# A64 register map
Vendor: Allwinner; Series: A64; File version: 0.1
CPU: CA53 0, little endian, MPU, no FPU, 0 interrupt priority bits
Registers are 32-bit, read-write, reset 0x0 unless marked. A register's access mark holds for its fields unless they carry their own. Offsets are from the block's base; [hi:lo] are bit positions; lines under a group give offsets from that group; {n}, {i} and the like mark numbered series; <NAME> marks a mode.

## SMC
Base 0x01C1E000
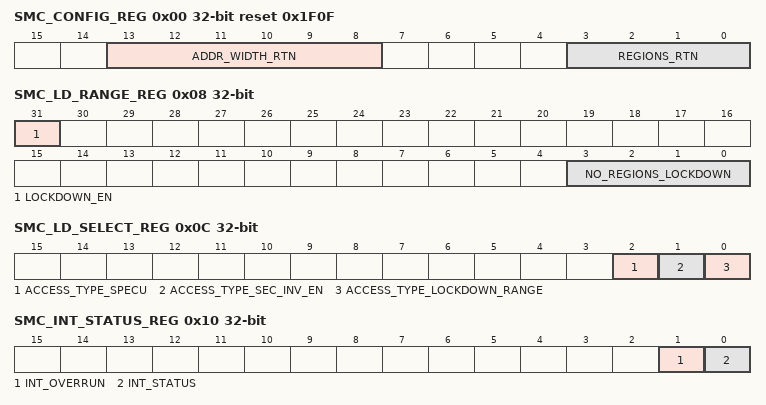
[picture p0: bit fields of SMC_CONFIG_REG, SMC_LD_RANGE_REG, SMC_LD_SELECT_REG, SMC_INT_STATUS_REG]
0x00 SMC_CONFIG_REG reset 0x1F0F — SMC Configuration Register
  [13:8] ADDR_WIDTH_RTN ro — Address width. Return the width of the AXI address bus. 6`b 000000-6`b011110 reserved. 6`b 011111 = 32-bit ... 6`b 111111 = 64-bit
  [3:0] REGIONS_RTN ro — Returns the number of the regions that the SMC provides. 4`b0000 = reserved 4`b0001 = 2 regions ... 4`b1111 = 16 regions.
0x04 SMC_ACTION_REG reset 0x1 — SMC Action Register
  [1:0] SMC_INT_RESP — Control how the SMC uses the bresps[1:0], rresps[1:0], and smc_int signals when a region permission failure occurs: 2`b00 = sets smc_int LOW and issues an OKEY response 2`b01 = sets smc_int LOW and issues a DECERR response 2`b10 = sets smc_int HIGH and issues an OKEY response 2`b11 = sets smc_int HIGH and issues a DECERR response
0x08 SMC_LD_RANGE_REG — SMC Lock Down Range Register
  [31] LOCKDOWN_EN — When set to 1, it enables the lockdown_regions field to control the regions that are to be locked.
  [3:0] NO_REGIONS_LOCKDOWN — Control the number of regions to lockdown when the enable bit is set to 1. 4`b0000 = region no_of_regions-1 is locked 4`b0001 = region no_of_regions-1 to region no_of_regions-2 are locked ... 4`b1111 = region no_of_regions-1 to region no_of_regions-16 are locked
0x0C SMC_LD_SELECT_REG — SMC Lock Down Select Register
  [2] ACCESS_TYPE_SPECU — Modify the access type of the speculation_control register: 0: no effect. The speculation register remains RW. 1: speculation_control register is RO
    0=no effect. The speculation register remains RW.; 1=speculation_control register is RO
  [1] ACCESS_TYPE_SEC_INV_EN — Modify the access type of the security_inversion_en register. 0: no effect. Security_inversion_en register remains RW. 1: security_inversion_en register is RO
    0=no effect. Security_inversion_en register remains RW.; 1=security_inversion_en register is RO
  [0] ACCESS_TYPE_LOCKDOWN_RANGE — Modify the access type of the lockdown_range register. 0: no effect. Lockdown_range register remains RW 1: lockdown_range register is RO.
    0=no effect. Lockdown_range register remains RW; 1=lockdown_range register is RO
0x10 SMC_INT_STATUS_REG — SMC Interrupt Status Register
  [1] INT_OVERRUN ro — When set to 1, it indicates the occurrence of two or more region permission failure since the interrupt was last cleared.
  [0] INT_STATUS ro — Return the status of the interrupt. 0: interrupt is inactive. 1: interrupt is active.
    0=inactive (interrupt is inactive.); 1=active (interrupt is active.)
0x14 SMC_INT_CLEAR_REG — SMC Interrupt Clear Register
  [31:0] SMC_CLR_REG — Write any value to the int_clear register sets the : Status bit to 0 in the int_status register Overrun bit to 0 in the int_status register. Note: It will be auto cleared after the write operation.
0x18 SMC_MST_BYP_REG reset 0xFFFFFFFF — SMC Master Bypass Register
  [31:0] SMC_MASTER_BYPASS_EN — SMC Master n Bypass Enable. (n = 0~31, see the . MASTER and MASTER ID for detail.) Note: Bit[31:0] stand for Master ID [31:0] If the master n bypass enable is set to 0, the master n access must be through the SMC. 0: Bypass Disable 1: Bypass Enable.
0x1C SMC_MST_SEC_REG — SMC Master Secure Register
  [31:0] SMC_MASTER_SEC — SMC Master n Secure Configuration.(n = 0~31 see the for detail) 0: secure 1: non-secure.
0x20 SMC_FAIL_ADDR_REG — SMC Fail Address Register
  [31:0] FIRST_ACCESS_FAIL ro — Return the address bits [31:0] of the first access to fail a region permission check after the interrupt was cleared. For external 16-bit DDR2, the address [2:0] is fixed to zero. For external 32-bit DDR2 and 16-bit DDR3, the address [3:0] is fixed to zero. For external 32-bit DDR3, the address [4:0] is fixed to zero.
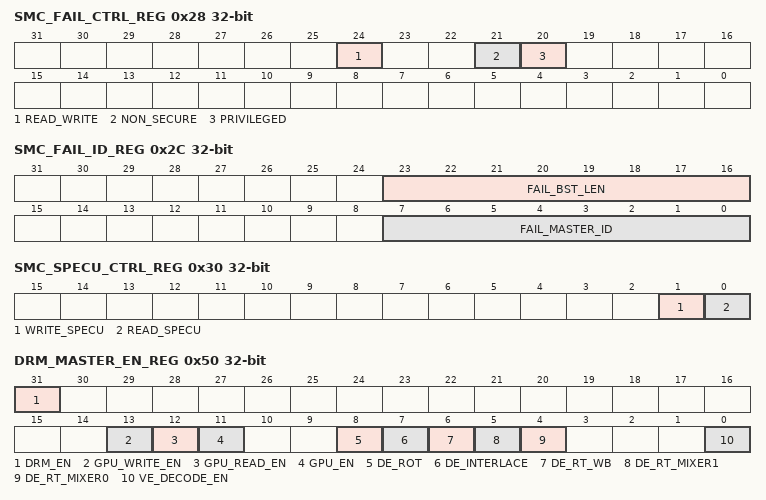
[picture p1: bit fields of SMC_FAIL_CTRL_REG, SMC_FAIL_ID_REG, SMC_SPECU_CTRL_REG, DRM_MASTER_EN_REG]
0x28 SMC_FAIL_CTRL_REG — SMC Fail Control Register
  [24] READ_WRITE ro — This bit indicates whether the first access to fail a region permission check was a write or read as: 0 = read access 1 = write access.
  [21] NON_SECURE ro — After clearing the interrupt status, this bit indicates whether the first access to fail a region permission check was non-secure. Read as: 0 = secure access 1 = non-secure access
  [20] PRIVILEGED ro — After clearing the interrupt status, this bit indicates whether the first access to fail a region permission check was privileged. Read as: 0 = unprivileged access. 1 = privileged access
0x2C SMC_FAIL_ID_REG — SMC Fail ID Register
  [23:16] FAIL_BST_LEN ro — Fail burst length. 0 = 1 word length ... 0xf =16 words length
  [7:0] FAIL_MASTER_ID ro — Fail Master ID. The value stands for master id, see the MASTER and MASTER ID for detail.
0x30 SMC_SPECU_CTRL_REG — SMC Speculation Control Register
  [1] WRITE_SPECU — Write_speculation. Control the write access speculation: 0 = write access speculation is enabled 1 = write access speculation is disabled.
  [0] READ_SPECU — Read_speculation. Control the read access speculation: 0 = read access speculation is enabled 1 = read access speculation is disabled.
0x34 SMC_SEC_INV_EN_REG — SMC Security Inversion Enable Register
  [0] SEC_INV_EN — Security_inversion_en. Controls whether the SMC permits security inversion to occur. 0 = security inversion is not permitted. 1 = security inversion is permitted. This enables a region to be accessible to masters in Non-secure state but not accessible to masters in Secure state. See and .
0x48 SMC_MST_ATTRI_REG — SMC Master Attribute Register
  [31:0] MST_ATTRI — 0: The secure attribute of master is up to master security extensions; 1: The secure attribute of master is up to .
0x50 DRM_MASTER_EN_REG — DRM Master Enable Register
  [31] DRM_EN — DRM enable.
  [13] GPU_WRITE_EN — GPU write enable.
  [12] GPU_READ_EN — GPU read enable.
  [11] GPU_EN — GPU enable When setted the bit to 1,bit12 and bit13 will be invalid.
  [8] DE_ROT — DE_ROT enable
  [7] DE_INTERLACE — DE_INTERLACE enable.
  [6] DE_RT_WB — DE_RT-WB enable.
  [5] DE_RT_MIXER1 — DE_RT-MIXER1 enable.
  [4] DE_RT_MIXER0 — DE_RT-MIXER0 enable.
  [0] VE_DECODE_EN — VE decode enable
0x58 DRM_ILLACCE_REG0
  [31:0] DRM_ILLACCE_REG ro — When a master, which is non-secure, accesses the DRM space, then the relevant bit will be set up. See for detail.
0x60 DRM_STATADDR_REG — DRM Start Address Register
  [31:15] DRM_STATADDR_REG
0x68 DRM_ENDADDR_REG — DRM End Address Register
  [31:15] DRM_ENDADDR_REG
{0x100+0x10*i} _N[{i}] (i=0..15) group
  0x00 SMC_REGION_SETUP_LO_REG — Region Setup Low Register N (N=0,1,2,3,4,5,6,7,8,9,10,11,12,13,14,15)
    [31:15] BASE_ADDRESS_LOW — Controls the base address [31:15] of region<n>. The SMC only permits a region to start at address 0x0, or at a multiple of its region size. For example, if the size of a region is 512MB, and it is not at address 0x0, the only valid settings for this field are: 17`b00100000000000000 17`b01000000000000000 17`b01100000000000000 17`b10000000000000000 17`b10100000000000000 17`b11000000000000000 17`b11100000000000000
  0x04 SMC_REGION_SETUP_HI_REG — Region Setup High Register N (N=0,1,2,3,4,5,6,7,8,9,10,11,12,13,14,15)
    [31:0] BASE_ADDRESS_HIGH — The SMC only permits a region to start at address 0x0, or at a multiple of its region size. If you program a region size to be 8GB or more, then the SMC might ignore certain bits depending on the region size.
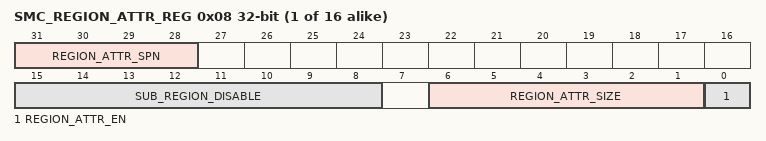
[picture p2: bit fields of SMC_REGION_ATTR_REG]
  0x08 SMC_REGION_ATTR_REG — Region Attribute Register N (N=0,1,2,3,4,5,6,7,8,9,10,11,12,13,14,15)
    [31:28] REGION_ATTR_SPN — SP<n>. Permission setting for region <n>. if an AXI transaction occurs to region n, the value in the sp<n> field controls whether the SMC permits the transaction to proceed. . See and .
    [15:8] SUB_REGION_DISABLE — Subregion_disable. Regions are split into eight equal-sized sub-regions, and each bit enables the corresponding subregion to be disabled. Bit [15] = 1 subregion 7 is disabled. Bit [14] = 1 subregion 6 is disabled. Bit [13] = 1 subregion 5 is disabled. Bit [12] = 1 subregion 4 is disabled. Bit [11] = 1 subregion 3 is disabled. Bit [10] = 1 subregion 2 is disabled. Bit [9] = 1 subregion 1 is disabled. Bit [8] = 1 subregion 0 is disabled.
    [6:1] REGION_ATTR_SIZE — Size<n>. Size of region<n>, see for detail.
    [0] REGION_ATTR_EN — EN<n>. Enable for region<n>. 0 = region < n> is disabled. 1 = region < n> is enabled.
